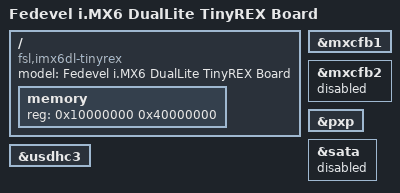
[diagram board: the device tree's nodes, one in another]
/*
 * Copyright (C) 2015 Voipac.
 *
 * The code contained herein is licensed under the GNU General Public
 * License. You may obtain a copy of the GNU General Public License
 * Version 2 or later at the following locations:
 *
 * http://www.opensource.org/licenses/gpl-license.html
 * http://www.gnu.org/copyleft/gpl.html
 */

/dts-v1/;

#include "imx6dl.dtsi"
#include "imx6qdl-tinyrex.dtsi"

/ {
	model = "Fedevel i.MX6 DualLite TinyREX Board";
	compatible = "fsl,imx6dl-tinyrex", "fsl,imx6dl";

	memory {
		reg = <0x10000000 0x40000000>;
	};
};

&mxcfb1 {
	status = "okay";
};

&mxcfb2 {
	status = "disabled";
};

&pxp {
	status = "okay";
};

&sata {
	status = "disabled";
};

&usdhc3 {
	status = "okay";
};
